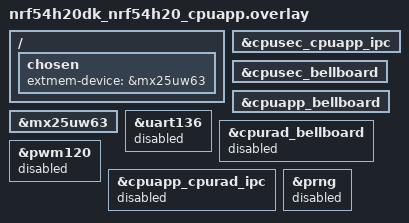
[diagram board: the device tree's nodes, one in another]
/*
 * Copyright (c) 2024 Nordic Semiconductor ASA
 *
 * SPDX-License-Identifier: LicenseRef-Nordic-5-Clause
 */

/ {
	chosen {
		extmem-device = &mx25uw63;
	};
};

&cpusec_cpuapp_ipc {
	status = "okay";
};

&cpusec_bellboard {
	status = "okay";
};

&cpuapp_bellboard {
	status = "okay";
};

&mx25uw63 {
	status = "okay";
};

&uart136 {
	status = "disabled";
};

&cpurad_bellboard {
	status = "disabled";
};

&pwm120 {
	status = "disabled";
};

&cpuapp_cpurad_ipc {
	status = "disabled";
};

&prng {
	status = "disabled";
};
